AUTOSAR XML (schema 00048)
package /HuaweiMDC/exe_manifests/swcs
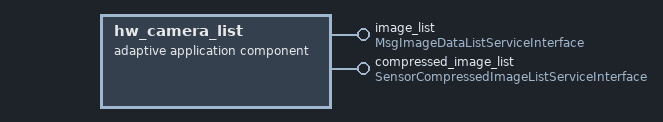
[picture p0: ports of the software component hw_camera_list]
  adaptive application sw component type hw_camera_list
    provide port image_list: provided-interface=MsgImageDataListServiceInterface
    provide port compressed_image_list: provided-interface=SensorCompressedImageListServiceInterface
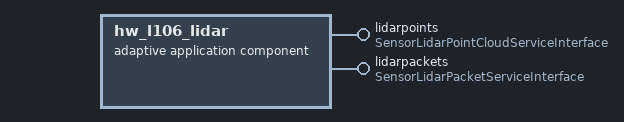
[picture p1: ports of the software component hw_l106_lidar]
  adaptive application sw component type hw_l106_lidar
    provide port lidarpoints: provided-interface=SensorLidarPointCloudServiceInterface
    provide port lidarpackets: provided-interface=SensorLidarPacketServiceInterface
  adaptive application sw component type mid_track_chassis_recv
    provide port tpvehiclestate: provided-interface=VehicleInfomationServiceInterface
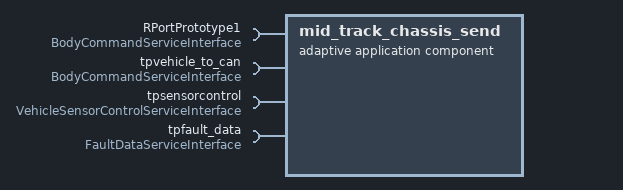
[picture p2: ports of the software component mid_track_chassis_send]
  adaptive application sw component type mid_track_chassis_send
    4 x require port:
      RPortPrototype1: required-interface=BodyCommandServiceInterface
      tpvehicle_to_can: required-interface=BodyCommandServiceInterface
      tpsensorcontrol: required-interface=VehicleSensorControlServiceInterface
      tpfault_data: required-interface=FaultDataServiceInterface
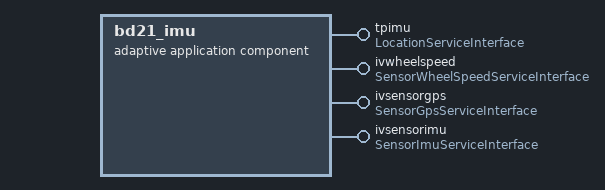
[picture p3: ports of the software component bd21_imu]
  adaptive application sw component type bd21_imu
    4 x provide port:
      tpimu: provided-interface=LocationServiceInterface
      ivwheelspeed: provided-interface=SensorWheelSpeedServiceInterface
      ivsensorgps: provided-interface=SensorGpsServiceInterface
      ivsensorimu: provided-interface=SensorImuServiceInterface
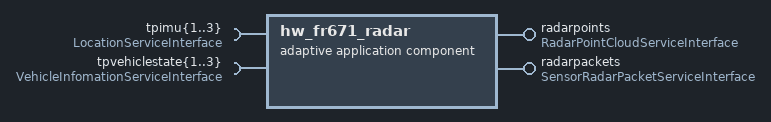
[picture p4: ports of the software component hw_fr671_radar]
  adaptive application sw component type hw_fr671_radar
    provide port radarpoints: provided-interface=RadarPointCloudServiceInterface
    provide port radarpackets: provided-interface=SensorRadarPacketServiceInterface
    6 x require port:
      tpimu{1..3}: required-interface=LocationServiceInterface
      tpvehiclestate{1..3}: required-interface=VehicleInfomationServiceInterface
  adaptive application sw component type lidar_lem_map_det_base
    provide port TerrainMapArrayPPortPrototype
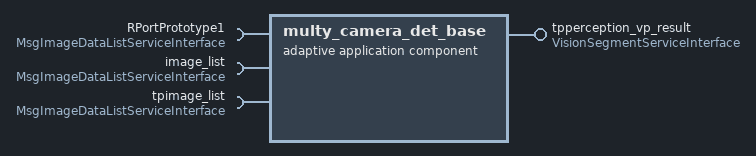
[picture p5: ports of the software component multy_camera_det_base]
  adaptive application sw component type multy_camera_det_base
    provide port tpperception_vp_result: provided-interface=VisionSegmentServiceInterface
    require port RPortPrototype1: required-interface=MsgImageDataListServiceInterface
    require port image_list: required-interface=MsgImageDataListServiceInterface
    require port tpimage_list: required-interface=MsgImageDataListServiceInterface
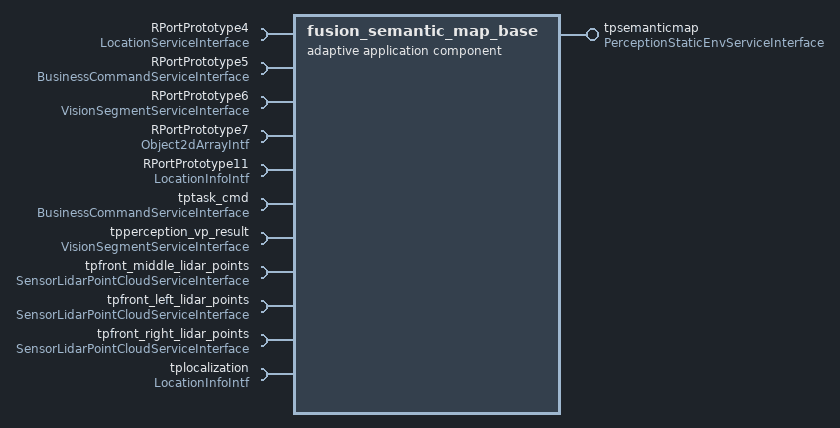
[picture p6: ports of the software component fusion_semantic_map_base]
  adaptive application sw component type fusion_semantic_map_base
    provide port tpsemanticmap: provided-interface=PerceptionStaticEnvServiceInterface
    11 x require port:
      RPortPrototype4: required-interface=LocationServiceInterface
      RPortPrototype5: required-interface=BusinessCommandServiceInterface
      RPortPrototype6: required-interface=VisionSegmentServiceInterface
      RPortPrototype7: required-interface=Object2dArrayIntf
      RPortPrototype11: required-interface=LocationInfoIntf
      tptask_cmd: required-interface=BusinessCommandServiceInterface
      tpperception_vp_result: required-interface=VisionSegmentServiceInterface
      tpfront_middle_lidar_points: required-interface=SensorLidarPointCloudServiceInterface
      tpfront_left_lidar_points: required-interface=SensorLidarPointCloudServiceInterface
      tpfront_right_lidar_points: required-interface=SensorLidarPointCloudServiceInterface
      tplocalization: required-interface=LocationInfoIntf
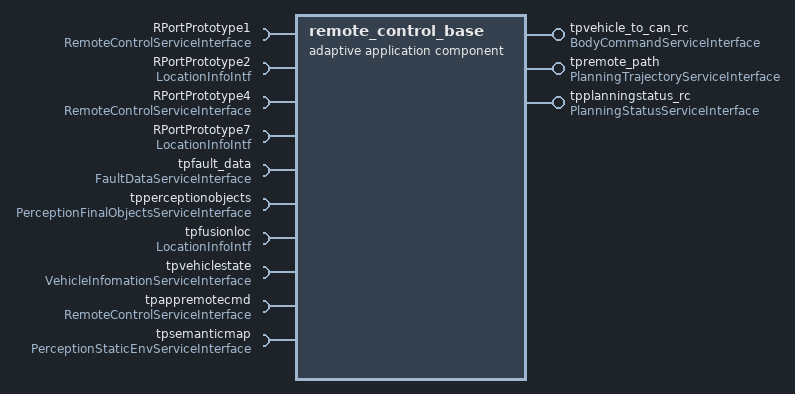
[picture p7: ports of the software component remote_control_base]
  adaptive application sw component type remote_control_base
    provide port tpvehicle_to_can_rc: provided-interface=BodyCommandServiceInterface
    5 x require port:
      RPortPrototype1: required-interface=RemoteControlServiceInterface
      RPortPrototype2: required-interface=LocationInfoIntf
      RPortPrototype4: required-interface=RemoteControlServiceInterface
      RPortPrototype7: required-interface=LocationInfoIntf
      tpfault_data: required-interface=FaultDataServiceInterface
    provide port tpremote_path: provided-interface=PlanningTrajectoryServiceInterface
    provide port tpplanningstatus_rc: provided-interface=PlanningStatusServiceInterface
    5 x require port:
      tpperceptionobjects: required-interface=PerceptionFinalObjectsServiceInterface
      tpfusionloc: required-interface=LocationInfoIntf
      tpvehiclestate: required-interface=VehicleInfomationServiceInterface
      tpappremotecmd: required-interface=RemoteControlServiceInterface
      tpsemanticmap: required-interface=PerceptionStaticEnvServiceInterface
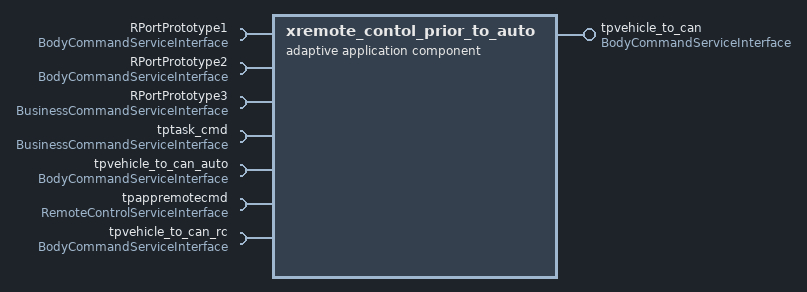
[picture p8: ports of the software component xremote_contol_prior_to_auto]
  adaptive application sw component type xremote_contol_prior_to_auto
    provide port tpvehicle_to_can: provided-interface=BodyCommandServiceInterface
    7 x require port:
      RPortPrototype1: required-interface=BodyCommandServiceInterface
      RPortPrototype2: required-interface=BodyCommandServiceInterface
      RPortPrototype3: required-interface=BusinessCommandServiceInterface
      tptask_cmd: required-interface=BusinessCommandServiceInterface
      tpvehicle_to_can_auto: required-interface=BodyCommandServiceInterface
      tpappremotecmd: required-interface=RemoteControlServiceInterface
      tpvehicle_to_can_rc: required-interface=BodyCommandServiceInterface
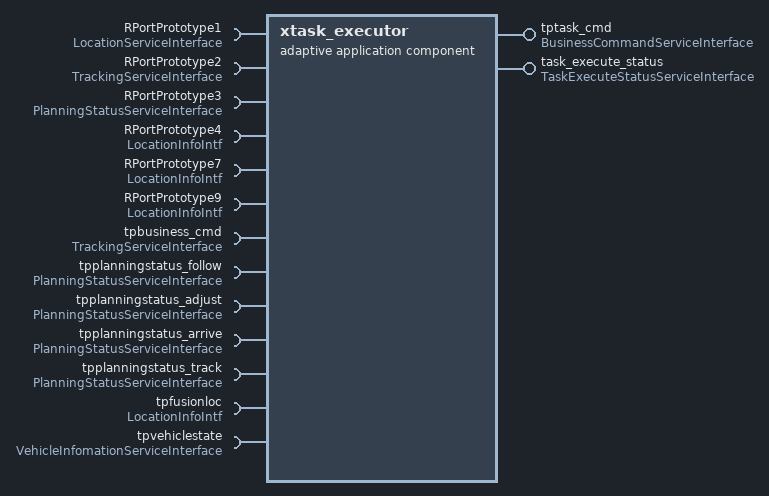
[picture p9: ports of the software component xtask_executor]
  adaptive application sw component type xtask_executor
    provide port tptask_cmd: provided-interface=BusinessCommandServiceInterface
    provide port task_execute_status: provided-interface=TaskExecuteStatusServiceInterface
    13 x require port:
      RPortPrototype1: required-interface=LocationServiceInterface
      RPortPrototype2: required-interface=TrackingServiceInterface
      RPortPrototype3: required-interface=PlanningStatusServiceInterface
      RPortPrototype4: required-interface=LocationInfoIntf
      RPortPrototype7: required-interface=LocationInfoIntf
      RPortPrototype9: required-interface=LocationInfoIntf
      tpbusiness_cmd: required-interface=TrackingServiceInterface
      tpplanningstatus_follow: required-interface=PlanningStatusServiceInterface
      tpplanningstatus_adjust: required-interface=PlanningStatusServiceInterface
      tpplanningstatus_arrive: required-interface=PlanningStatusServiceInterface
      tpplanningstatus_track: required-interface=PlanningStatusServiceInterface
      tpfusionloc: required-interface=LocationInfoIntf
      tpvehiclestate: required-interface=VehicleInfomationServiceInterface
  adaptive application sw component type xvideo_encoder
    provide port SensorImagePPortPrototype: provided-interface=SensorImageServiceInterface
    require port RPortPrototype1: required-interface=MsgImageDataListServiceInterface
    require port RPortPrototype2
  adaptive application sw component type xh265_rtp_pusher
    6 x require port:
      RPortPrototype1
      RPortPrototype2: required-interface=VideoRtpServiceInterface
      RPortPrototype3
      video_rtp_parameter_gcs: required-interface=VideoRtpServiceInterface
      RPortPrototype5
      video_encoded_frame: required-interface=SensorImageServiceInterface
  adaptive application sw component type xzmq_task
    provide port video_rtp_parameter_gcs: provided-interface=VideoRtpServiceInterface
    provide port video_profile: provided-interface=AppVideoProfileServiceInterface
    provide port tpbusiness_cmd: provided-interface=TrackingServiceInterface
    require port RPortPrototype1: required-interface=LocationInfoIntf
    provide port tpsensorcontrol: provided-interface=VehicleSensorControlServiceInterface
    provide port task_manage_status: provided-interface=TaskManageStatusServiceInterface
    7 x require port:
      RPortPrototype4: required-interface=LocationInfoIntf
      task_execute_status: required-interface=TaskExecuteStatusServiceInterface
      RPortPrototype3: required-interface=LocationInfoIntf
      tpvehiclestate: required-interface=VehicleInfomationServiceInterface
      tpperceptionobjects: required-interface=PerceptionFinalObjectsServiceInterface
      tptarget_obj: required-interface=FusionObjectArrayIntf
      tplocalization: required-interface=LocationInfoIntf
  adaptive application sw component type xzmq_rc
    provide port tpappremotecmd: provided-interface=RemoteControlServiceInterface
  adaptive application sw component type ApplicationSwc
  adaptive application sw component type xvideo_editor
    provide port SensorImagePPortPrototype: provided-interface=SensorImageServiceInterface
    require port RPortPrototype1: required-interface=MsgImageDataListServiceInterface
    require port RPortPrototype2
  adaptive application sw component type idptestswc1
    provide port PPortPrototype
  adaptive application sw component type xh265_encoder
    provide port video_encoded_frame: provided-interface=SensorImageServiceInterface
    4 x require port:
      RPortPrototype1: required-interface=SensorImageServiceInterface
      RPortPrototype2: required-interface=SensorImageServiceInterface
      tpimage_for_push: required-interface=SensorImageServiceInterface
      video_profile: required-interface=AppVideoProfileServiceInterface
    provide port video_encoding_perf: provided-interface=VideoEncodingPerfServiceInterface
  adaptive application sw component type hwfr671radarswc
    provide port SensorRadarPPortPrototype: provided-interface=Sensor4DRadarServiceInterface
  adaptive application sw component type locfusionswc
    provide port LocFusionPPortPrototype: provided-interface=LocationInfoIntf
    5 x require port:
      RPortPrototype2: required-interface=RadarPointCloudServiceInterface
      RPortPrototype3: required-interface=LocationServiceInterface
      RPortPrototype4: required-interface=SensorWheelSpeedServiceInterface
      RPortPrototype5: required-interface=SensorGpsServiceInterface
      RPortPrototype1: required-interface=SensorLidarPointCloudServiceInterface
  adaptive application sw component type rtspserverswc
    require port RPortPrototype1
    require port video_encoded_frame: required-interface=SensorImageServiceInterface
  adaptive application sw component type loc_message_fusion
    provide port tplocalization: provided-interface=LocationInfoIntf
    4 x require port:
      RPortPrototype{1..3}: required-interface=LocationInfoIntf
      RPortPrototype4: required-interface=LocationServiceInterface
  adaptive application sw component type lidar_terrain_map_detection
    provide port tpterrainmap: provided-interface=PerceptionStaticEnvServiceInterface
    6 x require port:
      tpfront_right_lidar_points: required-interface=SensorLidarPointCloudServiceInterface
      tpperception_vp_result: required-interface=VisionSegmentServiceInterface
      tplocalization: required-interface=LocationInfoIntf
      tptask_cmd: required-interface=BusinessCommandServiceInterface
      tpfront_middle_lidar_points: required-interface=SensorLidarPointCloudServiceInterface
      tpfront_left_lidar_points: required-interface=SensorLidarPointCloudServiceInterface
  adaptive application sw component type fusion_follow_base
    provide port tpperceptionobjects: provided-interface=PerceptionFinalObjectsServiceInterface
    provide port tptarget_obj: provided-interface=FusionObjectArrayIntf
    12 x require port:
      tptask_cmd: required-interface=BusinessCommandServiceInterface
      tpperception_vp_result: required-interface=VisionSegmentServiceInterface
      RPortPrototype3: required-interface=Object3dArrayIntf
      tpfront_middle_lidar_points: required-interface=SensorLidarPointCloudServiceInterface
      tpfront_left_lidar_points: required-interface=SensorLidarPointCloudServiceInterface
      tpfront_right_lidar_points: required-interface=SensorLidarPointCloudServiceInterface
      tpfront_middle_radar_points: required-interface=RadarPointCloudServiceInterface
      tpfront_left_radar_points: required-interface=RadarPointCloudServiceInterface
      tpfront_right_radar_points: required-interface=RadarPointCloudServiceInterface
      tplocalization: required-interface=LocationInfoIntf
      tplidarobjects: required-interface=Object3dArrayIntf
      tpperception_vp_result: required-interface=VisionSegmentServiceInterface
  adaptive application sw component type planning_adjust_base
    provide port tpplanningstatus_adjust: provided-interface=PlanningStatusServiceInterface
    provide port tppathplan_adjust: provided-interface=EgoTrajectoryServiceInterface
    7 x require port:
      RPortPrototype2: required-interface=LocationInfoIntf
      tptask_cmd: required-interface=BusinessCommandServiceInterface
      tpperceptionobjects: required-interface=PerceptionFinalObjectsServiceInterface
      tpterrainmap: required-interface=PerceptionStaticEnvServiceInterface
      tpfusionloc: required-interface=LocationInfoIntf
      tpvehiclestate: required-interface=VehicleInfomationServiceInterface
      tpsemanticmap: required-interface=PerceptionStaticEnvServiceInterface
  adaptive application sw component type object_following_base
    provide port tpplanningstatus_follow: provided-interface=PlanningStatusServiceInterface
    provide port tppathplan_follow: provided-interface=PlanningTrajectoryServiceInterface
    8 x require port:
      RPortPrototype2: required-interface=LocationInfoIntf
      tptask_cmd: required-interface=BusinessCommandServiceInterface
      tpperceptionobjects: required-interface=PerceptionFinalObjectsServiceInterface
      tpterrainmap: required-interface=PerceptionStaticEnvServiceInterface
      tplocalization: required-interface=LocationInfoIntf
      tpvehiclestate: required-interface=VehicleInfomationServiceInterface
      tpsemanticmap: required-interface=PerceptionStaticEnvServiceInterface
      tptarget_obj: required-interface=FusionObjectArrayIntf
  adaptive application sw component type planning_arrive_base
    provide port tpplanningstatus_arrive: provided-interface=PlanningStatusServiceInterface
    provide port tppathplan_arrive: provided-interface=PlanningTrajectoryServiceInterface
    7 x require port:
      RPortPrototype2: required-interface=LocationInfoIntf
      tptask_cmd: required-interface=BusinessCommandServiceInterface
      tpperceptionobjects: required-interface=PerceptionFinalObjectsServiceInterface
      tpterrainmap: required-interface=PerceptionStaticEnvServiceInterface
      tpfusionloc: required-interface=LocationInfoIntf
      tpvehiclestate: required-interface=VehicleInfomationServiceInterface
      tpsemanticmap: required-interface=PerceptionStaticEnvServiceInterface
  adaptive application sw component type aeb_control_base
    provide port tpvehicle_to_can_auto: provided-interface=BodyCommandServiceInterface
    10 x require port:
      tpvehicle_to_can_pre_aeb: required-interface=BodyCommandServiceInterface
      tpfault_data: required-interface=FaultDataServiceInterface
      tpvehiclestate: required-interface=VehicleInfomationServiceInterface
      RPortPrototype4: required-interface=LocationInfoIntf
      tptask_cmd: required-interface=BusinessCommandServiceInterface
      tpwheelspeed: required-interface=SensorWheelSpeedServiceInterface
      tpfusionloc: required-interface=LocationInfoIntf
      tppathplan_auto: required-interface=PlanningTrajectoryServiceInterface
      tpperceptionobjects: required-interface=PerceptionFinalObjectsServiceInterface
      tpsemanticmap: required-interface=PerceptionStaticEnvServiceInterface
  adaptive application sw component type path_selector_base
    provide port tppathplan_auto: provided-interface=PlanningTrajectoryServiceInterface
    5 x require port:
      tppathplan_adjust: required-interface=EgoTrajectoryServiceInterface
      tppathplan_arrive: required-interface=PlanningTrajectoryServiceInterface
      tppathplan_track: required-interface=PlanningResultIntf
      tppathplan_follow: required-interface=PlanningTrajectoryServiceInterface
      tptask_cmd: required-interface=BusinessCommandServiceInterface
  adaptive application sw component type xzmq_notification
    14 x require port:
      RPortPrototype2: required-interface=LocationInfoIntf
      video_profile: required-interface=AppVideoProfileServiceInterface
      tptask_cmd: required-interface=BusinessCommandServiceInterface
      task_manage_status: required-interface=TaskManageStatusServiceInterface
      tpperceptionobjects: required-interface=PerceptionFinalObjectsServiceInterface
      tptarget_obj: required-interface=FusionObjectArrayIntf
      ivsensorgps: required-interface=SensorGpsServiceInterface
      tpfusionloc: required-interface=LocationInfoIntf
      tpvehicle_to_can: required-interface=BodyCommandServiceInterface
      tpvehiclestate: required-interface=VehicleInfomationServiceInterface
      tpfault_data: required-interface=FaultDataServiceInterface
      tpsemanticmap: required-interface=PerceptionStaticEnvServiceInterface
      video_encoding_perf: required-interface=VideoEncodingPerfServiceInterface
      tpappremotecmd: required-interface=RemoteControlServiceInterface
  adaptive application sw component type mdc_camera_stitch_base
    provide port tpimage_stitich: provided-interface=SensorImageServiceInterface
    require port image_list: required-interface=MsgImageDataListServiceInterface
  adaptive application sw component type xvideo_selector
    require port RPortPrototype4: required-interface=LocationInfoIntf
    provide port tpimage_for_push: provided-interface=SensorImageServiceInterface
    16 x require port:
      tpvideo_profile: required-interface=AppVideoProfileServiceInterface
      tpappremotecmd: required-interface=RemoteControlServiceInterface
      tptask_cmd: required-interface=BusinessCommandServiceInterface
      PerceptionVPResult: required-interface=VisionSegmentServiceInterface
      tppathplan_auto: required-interface=PlanningTrajectoryServiceInterface
      tpremote_path: required-interface=PlanningTrajectoryServiceInterface
      tpimage_stitich: required-interface=SensorImageServiceInterface
      image_list: required-interface=MsgImageDataListServiceInterface
      tpfusionloc: required-interface=LocationInfoIntf
      tpvehiclestate: required-interface=VehicleInfomationServiceInterface
      tpplanningstatus_rc: required-interface=PlanningStatusServiceInterface
      tpplanningstatus_follow: required-interface=PlanningStatusServiceInterface
      tpplanningstatus_adjust: required-interface=PlanningStatusServiceInterface
      tpplanningstatus_arrive: required-interface=PlanningStatusServiceInterface
      tpplanningstatus_track: required-interface=PlanningStatusServiceInterface
      tpsemanticmap: required-interface=PerceptionStaticEnvServiceInterface
  adaptive application sw component type xputimage_shm_server_base
    provide port putimage_out: provided-interface=SensorImageServiceInterface
    require port RPortPrototype1
    require port RPortPrototype2: required-interface=MsgImageDataListServiceInterface
  adaptive application sw component type xdraw_assislines_server_base
    provide port drawassist_image_out: provided-interface=SensorImageServiceInterface
    require port RPortPrototype1
    require port RPortPrototype2: required-interface=SensorImageServiceInterface
  adaptive application sw component type xdraw_obstacles_server_base
    provide port drawassist_image_out: provided-interface=SensorImageServiceInterface
    require port RPortPrototype1: required-interface=SensorImageServiceInterface
    require port RPortPrototype2
  adaptive application sw component type ximage_layout_server_base
    provide port image_for_push: provided-interface=SensorImageServiceInterface
    4 x require port:
      RPortPrototype1: required-interface=SensorImageServiceInterface
      RPortPrototype2
      RPortPrototype3: required-interface=MsgImageDataListServiceInterface
      RPortPrototype4: required-interface=SensorImageServiceInterface
  adaptive application sw component type xh265_recorder
    require port video_encoded_frame: required-interface=SensorImageServiceInterface
  adaptive application sw component type xfault_handler_base
    provide port tpfault_data: provided-interface=FaultDataServiceInterface
    require port tpbusiness_cmd: required-interface=TrackingServiceInterface
    require port tpappremotecmd: required-interface=RemoteControlServiceInterface
  adaptive application sw component type xsystem_monitor
    provide port monitor_data: provided-interface=FaultDataServiceInterface
  adaptive application sw component type xsensor_recorder_base
    provide port recorder_data: provided-interface=FaultDataServiceInterface
    11 x require port:
      RPortPrototype1: required-interface=SensorCompressedImageListServiceInterface
      RPortPrototype{2..4}: required-interface=SensorLidarPacketServiceInterface
      RPortPrototype{5..7}: required-interface=SensorRadarPacketServiceInterface
      RPortPrototype8: required-interface=SensorGpsServiceInterface
      RPortPrototype9: required-interface=LocationServiceInterface
      RPortPrototype10: required-interface=SensorWheelSpeedServiceInterface
      RPortPrototype11: required-interface=VehicleInfomationServiceInterface
  adaptive application sw component type ApplicationSwc
  adaptive application sw component type xdata_trigger_recorder_base
    provide port bag_ondemand_status: provided-interface=BagStatusServiceInterface
    require port tpbusiness_cmd: required-interface=TrackingServiceInterface
    require port tpfault_data: required-interface=FaultDataServiceInterface
  adaptive application sw component type xvehicle_status_recorder_base
    provide port status_recorder: provided-interface=FaultDataServiceInterface
    11 x require port:
      RPortPrototype7: required-interface=LocationInfoIntf
      tpappremotecmd: required-interface=RemoteControlServiceInterface
      tpbusiness_cmd: required-interface=TrackingServiceInterface
      tppathplan_follow: required-interface=PlanningTrajectoryServiceInterface
      tpplanningstatus_follow: required-interface=PlanningStatusServiceInterface
      tpvehicle_to_can_pre_aeb: required-interface=BodyCommandServiceInterface
      tpfusionloc: required-interface=LocationInfoIntf
      ivsensorgps: required-interface=SensorGpsServiceInterface
      tpvehiclestate: required-interface=VehicleInfomationServiceInterface
      tpfault_data: required-interface=FaultDataServiceInterface
      image_list: required-interface=MsgImageDataListServiceInterface
  adaptive application sw component type dev_null_base
    8 x require port:
      RPortPrototype1: required-interface=BagStatusServiceInterface
      RPortPrototype2: required-interface=FaultDataServiceInterface
      RPortPrototype3: required-interface=FaultDataServiceInterface
      monitor_data: required-interface=FaultDataServiceInterface
      RPortPrototype5: required-interface=FaultDataServiceInterface
      RPortPrototype6: required-interface=FaultDataServiceInterface
      status_recorder: required-interface=FaultDataServiceInterface
      bag_ondemand_status: required-interface=BagStatusServiceInterface
  adaptive application sw component type driver_dev_null
    14 x require port:
      compressed_image_list: required-interface=SensorCompressedImageListServiceInterface
      lidarpacketsfront: required-interface=SensorLidarPacketServiceInterface
      lidarpacketsleft: required-interface=SensorLidarPacketServiceInterface
      lidarpacketsright: required-interface=SensorLidarPacketServiceInterface
      radarpacketsright: required-interface=SensorRadarPacketServiceInterface
      radarpacketsfront: required-interface=SensorRadarPacketServiceInterface
      radarpacketsleft: required-interface=SensorRadarPacketServiceInterface
      RPortPrototype1: required-interface=SensorCompressedImageListServiceInterface
      RPortPrototype{2..4}: required-interface=SensorRadarPacketServiceInterface
      RPortPrototype{5..7}: required-interface=SensorLidarPacketServiceInterface
  adaptive application sw component type ApplicationSwc
  adaptive application sw component type ApplicationSwc
    provide port PPortPrototype
  adaptive application sw component type sensor_viualize_base
    4 x require port:
      tplidarfront: required-interface=SensorLidarPointCloudServiceInterface
      tpcameralist: required-interface=MsgImageDataListServiceInterface
      RPortPrototype1: required-interface=RadarPointCloudServiceInterface
      tpfusionloc: required-interface=LocationInfoIntf
  adaptive application sw component type planning_base
    require port RPortPrototype1: required-interface=PerceptionStaticEnvServiceInterface
    require port RPortPrototype2: required-interface=FusionObjectArrayIntf
package /HuaweiMDC/interface_manifests/interfaces
  30 x service interface:
    MsgImageDataListServiceInterface
      namespaces:
        symbol props ara
        symbol props adsfi
      events:
        data EventImageList: type=MsgImageDataList
    SensorCompressedImageListServiceInterface
      namespaces:
        symbol props ara
        symbol props adsfi
      events:
        data EventCompressedImageList: type=MsgImageDataList
    SensorLidarPointCloudServiceInterface
      namespaces:
        symbol props ara
        symbol props adsfi
      events:
        data EventPointCloud2: type=MsgLidarFrame
    SensorLidarPacketServiceInterface
      namespaces:
        symbol props ara
        symbol props adsfi
      events:
        data EventLidarPacket: type=SensorLidarPacket
    VehicleInfomationServiceInterface
      namespaces:
        symbol props ara
        symbol props adsfi
      events:
        data EventVehicleInfo: type=VehicleInformation
    SensorGpsServiceInterface
      namespaces:
        symbol props ara
        symbol props adsfi
      events:
        data EventGps: type=MsgHafGnssInfo
    SensorWheelSpeedServiceInterface
      namespaces:
        symbol props ara
        symbol props adsfi
      events:
        data EventWheelSpeed: type=MsgHafWheelSpeedList
    VisionSegmentServiceInterface
      namespaces:
        symbol props ara
        symbol props adsfi
      events:
        data EventVisionSegment: type=MsgCameraVPResult
    FusionObjectServiceInterface
      namespaces:
        symbol props ara
        symbol props adsfi
      events:
        data EventFusionObject: type=FusionObject
    BusinessCommandServiceInterface
      namespaces:
        symbol props ara
        symbol props adsfi
      events:
        data EventBusinessCommand: type=BusinessCommand
    TaskExecuteStatusServiceInterface
      namespaces:
        symbol props ara
        symbol props adsfi
      events:
        data EventTaskExecuteStatus: type=TaskExecuteStatus
    SensorImageServiceInterface
      namespaces:
        symbol props ara
        symbol props adsfi
      events:
        data EventSensorImage: type=MsgImageData
    VideoRtpServiceInterface
      namespaces:
        symbol props ara
        symbol props adsfi
      events:
        data EventVideoRtpParamter: type=VideoRTPParameter
    TrackingServiceInterface
      namespaces:
        symbol props ara
        symbol props adsif
      events:
        data EventBusinessCommand: type=BusinessCommand
    RadarPointCloudServiceInterface
      namespaces:
        symbol props ara
        symbol props adsfi
      events:
        data EventRadarPointCloud: type=SensorRadarPointCloud
    SensorRadarPacketServiceInterface
      namespaces:
        symbol props ara
        symbol props adsfi
      events:
        data EventSensorRadarPacket: type=SensorRadarPacket
    BodyCommandServiceInterface
      namespaces:
        symbol props ara
        symbol props adsfi
      events:
        data EventVehicleActControl: type=VehicleActControl
    RemoteControlServiceInterface
      namespaces:
        symbol props ara
        symbol props adsfi
      events:
        data EventRCAppRemoteCtl: type=AppRemoteControl
    PlanningStatusServiceInterface
      namespaces:
        symbol props ara
        symbol props adsfi
      events:
        data EventPlanningStatus: type=PlanningStatus
    Sensor4DRadarServiceInterface
      namespaces:
        symbol props ara
        symbol props adsfi
    SensorImuServiceInterface
      namespaces:
        symbol props ara
        symbol props adsfi
      events:
        data EventSensorImu: type=MsgHafIMU
    PerceptionStaticEnvServiceInterface
      namespaces:
        symbol props ara
        symbol props adsfi
      events:
        data EventPerceptionStaticEnv: type=PerceptionStaticEnv
    PerceptionFinalObjectsServiceInterface
      namespaces:
        symbol props ara
        symbol props adsfi
      events:
        data EventPerceptionFinalObjects: type=MsgHafFusionOutArray
    PlanningTrajectoryServiceInterface
      namespaces:
        symbol props ara
        symbol props adsfi
      events:
        data EventPlanningTrajectory: type=MsgHafEgoTrajectory
    TaskManageStatusServiceInterface
      namespaces:
        symbol props ara
        symbol props adsfi
      events:
        data EventTaskManageStatus: type=TaskManageStatus
    AppVideoProfileServiceInterface
      namespaces:
        symbol props ara
        symbol props adsfi
      events:
        data EventAppVideoProfile: type=AppVideoProfile
    VehicleSensorControlServiceInterface
      namespaces:
        symbol props ara
        symbol props adsfi
      events:
        data EventVehicleSensorControl: type=VehicleSensorControl
    FaultDataServiceInterface
      namespaces:
        symbol props ara
        symbol props adsfi
      events:
        data EventFaultData: type=FaultData
    BagStatusServiceInterface
      namespaces:
        symbol props ara
        symbol props adsfi
      events:
        data EventBagStatus: type=FaultData
    VideoEncodingPerfServiceInterface
      namespaces:
        symbol props ara
        symbol props adsfi
      events:
        data EventVideoEncodingPerf: type=VideoEncodingPerf
package /HuaweiMDC/interface_manifests/datatypes
  155 x std cpp implementation data type:
    IdpStringVec: category=VECTOR, cpp-template-argument=String
      namespaces:
        symbol props ara
        symbol props adsfi
    IdpInt64Vec: category=VECTOR, cpp-template-argument=int64_t
      namespaces:
        symbol props ara
        symbol props adsfi
    IdpInt32Vec: category=VECTOR, cpp-template-argument=int32_t
      namespaces:
        symbol props ara
        symbol props adsfi
    IdpInt16Vec: category=VECTOR, cpp-template-argument=int16_t
      namespaces:
        symbol props ara
        symbol props adsfi
    IdpInt8Vec: category=VECTOR, cpp-template-argument=int8_t
      namespaces:
        symbol props ara
        symbol props adsfi
    IdpDoubleVec: category=VECTOR, cpp-template-argument=double
      namespaces:
        symbol props ara
        symbol props adsfi
    IdpFloatVec: category=VECTOR, cpp-template-argument=float
      namespaces:
        symbol props ara
        symbol props adsfi
    IdpUint64Vec: category=VECTOR, cpp-template-argument=uint64_t
      namespaces:
        symbol props ara
        symbol props adsfi
    IdpUint32Vec: category=VECTOR, cpp-template-argument=uint32_t
      namespaces:
        symbol props ara
        symbol props adsfi
    IdpUint16Vec: category=VECTOR, cpp-template-argument=uint16_t
      namespaces:
        symbol props ara
        symbol props adsfi
    IdpUint8Vec: category=VECTOR, cpp-template-argument=uint8_t
      namespaces:
        symbol props ara
        symbol props adsfi
    IdpBoolVec: category=VECTOR, cpp-template-argument=bool
      namespaces:
        symbol props ara
        symbol props adsfi
    MsgHafFloat32WithValid: category=STRUCTURE
      namespaces:
        symbol props ara
        symbol props adsfi
      cpp implementation data type element value: type-reference=float
      cpp implementation data type element confidence: type-reference=uint8_t
    MsgHafTime: category=STRUCTURE
      namespaces:
        symbol props ara
        symbol props adsfi
      cpp implementation data type element sec: type-reference=uint32_t
      cpp implementation data type element nsec: type-reference=uint32_t
    CommonFaultInfo: category=STRUCTURE
      namespaces:
        symbol props ara
        symbol props adsfi
      cpp implementation data type element t: type-reference=double
      cpp implementation data type element info: type-reference=String
      cpp implementation data type element error_code: type-reference=int32_t
    CommonFaultInfoVec: category=VECTOR, cpp-template-argument=CommonFaultInfo
      namespaces:
        symbol props ara
        symbol props adsfi
    CommonTimeChain: category=STRUCTURE
      namespaces:
        symbol props ara
        symbol props adsfi
      4 x cpp implementation data type element, all with category=TYPE_REFERENCE:
        t1: type-reference=double
        t2: type-reference=double
        from_module: type-reference=String
        to_module: type-reference=String
    CommonTimeChainVec: category=VECTOR, cpp-template-argument=CommonTimeChain
      namespaces:
        symbol props ara
        symbol props adsfi
    CommonHeader: category=STRUCTURE
      namespaces:
        symbol props ara
        symbol props adsfi
      7 x cpp implementation data type element, all with category=TYPE_REFERENCE:
        seq: type-reference=int64_t
        time: type-reference=MsgHafTime
        module_name: type-reference=String
        data_name: type-reference=String
        frame_id: type-reference=String
        fault_vec: type-reference=CommonFaultInfoVec
        time_chain_vec: type-reference=datatypes/CommonTimeChainVec
    CommonSensorCalibration: category=STRUCTURE
      namespaces:
        symbol props ara
        symbol props adsfi
      14 x cpp implementation data type element, all with category=TYPE_REFERENCE:
        name: type-reference=String
        prerotaxis_{0..2}: type-reference=int32_t
        prerotdegree_{0..2}: type-reference=float
        xoffset: type-reference=float
        yoffset: type-reference=float
        zoffset: type-reference=float
        roll: type-reference=float
        pitch: type-reference=float
        yaw: type-reference=float
        z_ground_offset: type-reference=float
    CommonUdpPacket: category=STRUCTURE
      namespaces:
        symbol props ara
        symbol props adsfi
      cpp implementation data type element header: type-reference=CommonHeader
      cpp implementation data type element udp_packet: type-reference=IdpUint8Vec
    CommonUdpPacketVec: category=VECTOR, cpp-template-argument=CommonUdpPacket
      namespaces:
        symbol props ara
        symbol props adsfi
    SensorLidarPacket: category=STRUCTURE
      namespaces:
        symbol props ara
        symbol props adsfi
      4 x cpp implementation data type element, all with category=TYPE_REFERENCE:
        header: type-reference=CommonHeader
        calibration: type-reference=CommonSensorCalibration
        msop_packet: type-reference=datatypes/CommonUdpPacketVec
        difop_packet: type-reference=CommonUdpPacket
    MsgPoint3D: category=STRUCTURE
      namespaces:
        symbol props ara
        symbol props adsfi
      cpp implementation data type element x: type-reference=double
      cpp implementation data type element y: type-reference=double
      cpp implementation data type element z: type-reference=double
    MsgPoint3DVec: category=VECTOR, cpp-template-argument=MsgPoint3D
      namespaces:
        symbol props ara
        symbol props adsfi
    MsgHafRect3D: category=STRUCTURE
      namespaces:
        symbol props ara
        symbol props adsfi
      7 x cpp implementation data type element, all with category=TYPE_REFERENCE:
        center: type-reference=MsgPoint3D
        centerCovariance: type-reference=MsgPoint3D
        size: type-reference=MsgPoint3D
        sizeCovariance: type-reference=MsgPoint3D
        orientation: type-reference=float
        orientationCovariance: type-reference=float
        corners: type-reference=datatypes/MsgPoint3DVec
    MsgPoint3f: category=STRUCTURE
      namespaces:
        symbol props ara
        symbol props adsfi
      cpp implementation data type element x: type-reference=float
      cpp implementation data type element y: type-reference=float
      cpp implementation data type element z: type-reference=float
    MsgPoint3fVec: category=VECTOR, cpp-template-argument=MsgPoint3f
      namespaces:
        symbol props ara
        symbol props adsfi
    MsgHaf3dDetectionOut: category=STRUCTURE
      namespaces:
        symbol props ara
        symbol props adsfi
      14 x cpp implementation data type element, all with category=TYPE_REFERENCE:
        objectId: type-reference=int32_t
        cls: type-reference=uint32_t
        types: type-reference=uint32_t
        confidence: type-reference=float
        existenceProbability: type-reference=float
        coordinate: type-reference=String
        rect: type-reference=MsgHafRect3D
        velocity: type-reference=MsgPoint3f
        contourPoints: type-reference=datatypes/MsgPoint3fVec
        timeCreation: type-reference=MsgHafTime
        acceleration: type-reference=MsgPoint3D
        blinkerStatus: type-reference=uint32_t
        cipvFlag: type-reference=uint32_t
        cameraStatus: type-reference=uint8_t
    AppStatusMessage: category=STRUCTURE
      namespaces:
        symbol props ara
        symbol props adsfi
      cpp implementation data type element status: type-reference=String
      cpp implementation data type element error_msg: type-reference=String
    VehicleSensorControl: category=STRUCTURE
      namespaces:
        symbol props ara
        symbol props adsfi
      31 x cpp implementation data type element, all with category=TYPE_REFERENCE:
        header: type-reference=CommonHeader
        chassis_enable: type-reference=uint8_t
        operate_mode: type-reference=uint8_t
        motor_mode: type-reference=uint8_t
        motor_power: type-reference=uint8_t
        limit_speed: type-reference=uint8_t
        high_pressure: type-reference=uint8_t
        motor_drive_mode: type-reference=uint8_t
        offroad_mode: type-reference=uint8_t
        parking_mode: type-reference=uint8_t
        pump_control1: type-reference=uint8_t
        pump_control2: type-reference=uint8_t
        flann_control: type-reference=uint8_t
        headlights_low_beam: type-reference=uint8_t
        headlights_hight_beam: type-reference=uint8_t
        turnleft_light: type-reference=uint8_t
        turnright_light: type-reference=uint8_t
        position_light: type-reference=uint8_t
        double_floash: type-reference=uint8_t
        horn: type-reference=uint8_t
        drainage_pump: type-reference=uint8_t
        radar_control: type-reference=uint8_t
        lidar_control: type-reference=uint8_t
        night_vision_control: type-reference=uint8_t
        domain_control: type-reference=uint8_t
        MDC_temp: type-reference=uint8_t
        reserve1: type-reference=uint8_t
        reserve2: type-reference=uint8_t
        battery_heating: type-reference=uint8_t
        power_out_control: type-reference=uint8_t
        battery_warming: type-reference=uint8_t
    VehicleLonControl: category=STRUCTURE
      namespaces:
        symbol props ara
        symbol props adsfi
      8 x cpp implementation data type element, all with category=TYPE_REFERENCE:
        target_speed: type-reference=float
        target_torque: type-reference=float
        target_pressure: type-reference=float
        actuator_mode: type-reference=uint8_t
        emergency_mode: type-reference=uint8_t
        handbrake: type-reference=uint8_t
        shift_position: type-reference=uint8_t
        control_mode: type-reference=uint8_t
    MsgHafRadarModeDatainfo: category=STRUCTURE
      namespaces:
        symbol props ara
        symbol props adsfi
      5 x cpp implementation data type element, all with category=TYPE_REFERENCE:
        x: type-reference=double
        y: type-reference=double
        z: type-reference=double
        rms: type-reference=MsgPoint3D
        quality: type-reference=MsgPoint3D
    MsgHafRadarDetectData: category=STRUCTURE
      namespaces:
        symbol props ara
        symbol props adsfi
      13 x cpp implementation data type element, all with category=TYPE_REFERENCE:
        id: type-reference=uint8_t
        idPair: type-reference=uint8_t
        coordinate: type-reference=uint8_t
        position: type-reference=MsgHafRadarModeDatainfo
        velocity: type-reference=MsgHafRadarModeDatainfo
        acceleration: type-reference=MsgHafRadarModeDatainfo
        rcs: type-reference=double
        snr: type-reference=double
        existProbability: type-reference=uint8_t
        falseProbability: type-reference=uint8_t
        movProperty: type-reference=uint8_t
        invalidState: type-reference=uint8_t
        ambiguity: type-reference=uint8_t
    BusniessRemoteControl: category=STRUCTURE
      namespaces:
        symbol props ara
        symbol props adsfi
      11 x cpp implementation data type element, all with category=TYPE_REFERENCE:
        steering_wheel: type-reference=double
        gear: type-reference=int32_t
        brake: type-reference=double
        accelerator: type-reference=double
        remotectrl_flag: type-reference=int32_t
        estop_flag: type-reference=int32_t
        steer_torque: type-reference=double
        eng_status: type-reference=bool
        ctrl_level: type-reference=int32_t
        tick: type-reference=int32_t
        in_place: type-reference=bool
    VehicleLatControl: category=STRUCTURE
      namespaces:
        symbol props ara
        symbol props adsfi
      5 x cpp implementation data type element, all with category=TYPE_REFERENCE:
        target_angle: type-reference=float
        target_torque: type-reference=float
        centor_control_value: type-reference=int8_t
        target_curvature: type-reference=float
        steer_control_mode: type-reference=int32_t
    CommonTimeChainVec: category=VECTOR, cpp-template-argument=CommonTimeChain
      namespaces:
        symbol props ara
        symbol props adsfi
    MsgPoint2D: category=STRUCTURE
      namespaces:
        symbol props ara
        symbol props adsfi
      cpp implementation data type element x: type-reference=double
      cpp implementation data type element y: type-reference=double
    MsgPoint2DVec: category=VECTOR, cpp-template-argument=MsgPoint2D
      namespaces:
        symbol props ara
        symbol props adsfi
    MsgHafRect2D: category=STRUCTURE
      namespaces:
        symbol props ara
        symbol props adsfi
      8 x cpp implementation data type element, all with category=TYPE_REFERENCE:
        center: type-reference=MsgPoint2D
        location: type-reference=MsgPoint2D
        centerCovariance: type-reference=MsgPoint2D
        size: type-reference=MsgPoint2D
        sizeCovariance: type-reference=MsgPoint2D
        orientation: type-reference=float
        orientationCovariance: type-reference=float
        corners: type-reference=datatypes/MsgPoint2DVec
    MsgPoint3DVec: category=VECTOR, cpp-template-argument=MsgPoint3D
      namespaces:
        symbol props ara
        symbol props adsfi
    MsgHafFusionOut: category=STRUCTURE
      namespaces:
        symbol props ara
        symbol props adsfi
      23 x cpp implementation data type element, all with category=TYPE_REFERENCE:
        objectID: type-reference=int32_t
        cs: type-reference=uint32_t
        confidence: type-reference=float
        existenceProbability: type-reference=float
        rect: type-reference=MsgHafRect3D
        rect_2d: type-reference=MsgHafRect2D
        absRect: type-reference=MsgHafRect3D
        velocity: type-reference=MsgPoint3f
        absVelocity: type-reference=MsgPoint3f
        velocityCovariance: type-reference=IdpDoubleVec
        absVelocityCovariance: type-reference=IdpDoubleVec
        acceleration: type-reference=MsgPoint3D
        absAcceleration: type-reference=MsgPoint3D
        accelerationCovariance: type-reference=IdpDoubleVec
        absAccelerationCovariance: type-reference=IdpDoubleVec
        pathPoints: type-reference=datatypes/MsgPoint3DVec
        timeCreation: type-reference=MsgHafTime
        lastUpdatedTime: type-reference=MsgHafTime
        cipvFlag: type-reference=uint8_t
        blinkerFlag: type-reference=uint8_t
        fusionType: type-reference=uint8_t
        anchorPoint: type-reference=MsgPoint3D
        absAnchorPoint: type-reference=MsgPoint3D
    MsgHafFusionOutVec: category=VECTOR, cpp-template-argument=MsgHafFusionOut
      namespaces:
        symbol props ara
        symbol props adsfi
    MsgHafFusionOutArray: category=STRUCTURE
      namespaces:
        symbol props ara
        symbol props adsfi
      6 x cpp implementation data type element, all with category=TYPE_REFERENCE:
        stamp: type-reference=MsgHafTime
        time_chain_vec: type-reference=datatypes/CommonTimeChainVec
        count: type-reference=int32_t
        fusionOut: type-reference=MsgHafFusionOutVec
        frameID: type-reference=String
        seq: type-reference=uint32_t
    CommonTimeChainVec: category=VECTOR, cpp-template-argument=CommonTimeChain
      namespaces:
        symbol props ara
        symbol props adsfi
    MsgHafHeader: category=STRUCTURE
      namespaces:
        symbol props ara
        symbol props adsfi
      4 x cpp implementation data type element, all with category=TYPE_REFERENCE:
        seq: type-reference=uint32_t
        timestamp: type-reference=MsgHafTime
        frameID: type-reference=String
        time_chain_vec: type-reference=datatypes/CommonTimeChainVec
    MsgHafWayPoint: category=STRUCTURE
      namespaces:
        symbol props ara
        symbol props adsfi
      14 x cpp implementation data type element, all with category=TYPE_REFERENCE:
        header: type-reference=MsgHafHeader
        xg: type-reference=double
        yg: type-reference=double
        zg: type-reference=double
        x: type-reference=double
        y: type-reference=double
        angle: type-reference=double
        theta: type-reference=double
        curvature: type-reference=double
        s: type-reference=double
        deltaCurvature: type-reference=double
        laneId: type-reference=String
        deltaX: type-reference=double
        deltaY: type-reference=double
    MsgHafTrajectoryPoint: category=STRUCTURE
      namespaces:
        symbol props ara
        symbol props adsfi
      9 x cpp implementation data type element, all with category=TYPE_REFERENCE:
        header: type-reference=MsgHafHeader
        wayPoint: type-reference=MsgHafWayPoint
        speed: type-reference=double
        acc: type-reference=double
        timeRelative: type-reference=double
        deltaAcc: type-reference=double
        steerAngle: type-reference=double
        length: type-reference=float
        risk_level: type-reference=int32_t
    MsgHafTrajectoryPointVec: category=VECTOR, cpp-template-argument=MsgHafTrajectoryPoint
      namespaces:
        symbol props ara
        symbol props adsfi
    MsgHafWayPointVec: category=VECTOR, cpp-template-argument=MsgHafWayPoint
      namespaces:
        symbol props ara
        symbol props adsfi
    MsgHafEstop: category=STRUCTURE
      namespaces:
        symbol props ara
        symbol props adsfi
      cpp implementation data type element header: type-reference=MsgHafHeader
      cpp implementation data type element isEstop: type-reference=uint8_t
      cpp implementation data type element description: type-reference=String
    MsgHafEgoTrajectory: category=STRUCTURE
      namespaces:
        symbol props ara
        symbol props adsfi
      14 x cpp implementation data type element, all with category=TYPE_REFERENCE:
        egoTrajectoryHeader: type-reference=MsgHafHeader
        trajectoryLength: type-reference=double
        trajectoryPeriod: type-reference=double
        trajectoryPoints: type-reference=MsgHafTrajectoryPointVec
        wayPoints: type-reference=MsgHafWayPointVec
        isReplanning: type-reference=uint8_t
        gear: type-reference=uint8_t
        estop: type-reference=MsgHafEstop
        routingHeader: type-reference=MsgHafHeader
        selfLaneid: type-reference=String
        trajectoryType: type-reference=int32_t
        targetLaneId: type-reference=String
        turnLight: type-reference=uint8_t
        isHeld: type-reference=uint8_t
    MsgPoint3DVec: category=VECTOR, cpp-template-argument=MsgPoint3D
      namespaces:
        symbol props ara
        symbol props adsfi
    AppVideoSplitPoint: category=STRUCTURE
      namespaces:
        symbol props ara
        symbol props adsfi
      4 x cpp implementation data type element, all with category=TYPE_REFERENCE, type-reference=int32_t:
        left_top_point_x
        left_top_point_y
        right_bottom_point_x
        right_bottom_point_y
    AppVideoSplitParam: category=STRUCTURE
      namespaces:
        symbol props ara
        symbol props adsfi
      cpp implementation data type element channel_name: type-reference=String
      cpp implementation data type element view_area_points: type-reference=AppVideoSplitPoint
      cpp implementation data type element crop_area_points: type-reference=AppVideoSplitPoint
    AppVideoSplitParamVec: category=VECTOR, cpp-template-argument=AppVideoSplitParam
      namespaces:
        symbol props ara
        symbol props adsfi
    AppVideoEditorParameter: category=STRUCTURE
      namespaces:
        symbol props ara
        symbol props adsfi
      15 x cpp implementation data type element, all with category=TYPE_REFERENCE:
        output_mode: type-reference=int32_t
        remote_control_alarm: type-reference=int32_t
        remote_control_assist: type-reference=int32_t
        front_source: type-reference=int32_t
        split_adaptive: type-reference=int32_t
        video_left_: type-reference=int32_t
        video_main_: type-reference=int32_t
        video_right_: type-reference=int32_t
        objects: type-reference=MsgHafFusionOutArray
        remote_control: type-reference=MsgHafEgoTrajectory
        path: type-reference=MsgHafEgoTrajectory
        target_points: type-reference=datatypes/MsgPoint3DVec
        video_third_person: type-reference=int32_t
        target_point: type-reference=MsgPoint3D
        split_parames_: type-reference=datatypes/AppVideoSplitParamVec
    MsgHafPose: category=STRUCTURE
      namespaces:
        symbol props ara
        symbol props adsfi
      cpp implementation data type element position: type-reference=MsgPoint3D
      cpp implementation data type element orientation: type-reference=MsgPoint3D
    MsgHafPoseWithCovariance: category=STRUCTURE
      namespaces:
        symbol props ara
        symbol props adsfi
      cpp implementation data type element pose: type-reference=MsgHafPose
      cpp implementation data type element covariance: type-reference=IdpDoubleVec
    MsgHafTwist: category=STRUCTURE
      namespaces:
        symbol props ara
        symbol props adsfi
      cpp implementation data type element linear: type-reference=MsgPoint3D
      cpp implementation data type element angular: type-reference=MsgPoint3D
    MsgHafTwistWithCovariance: category=STRUCTURE
      namespaces:
        symbol props ara
        symbol props adsfi
      cpp implementation data type element twist: type-reference=MsgHafTwist
      cpp implementation data type element covariance: type-reference=IdpDoubleVec
    MsgHafAccel: category=STRUCTURE
      namespaces:
        symbol props ara
        symbol props adsfi
      cpp implementation data type element linear: type-reference=MsgPoint3D
      cpp implementation data type element angular: type-reference=MsgPoint3D
    MsgHafAccelWithCovariance: category=STRUCTURE
      namespaces:
        symbol props ara
        symbol props adsfi
      cpp implementation data type element accel: type-reference=MsgHafAccel
      cpp implementation data type element covariance: type-reference=IdpDoubleVec
    MsgHafLocation: category=STRUCTURE
      namespaces:
        symbol props ara
        symbol props adsfi
      10 x cpp implementation data type element, all with category=TYPE_REFERENCE:
        header: type-reference=MsgHafHeader
        llh: type-reference=MsgPoint3D
        pose: type-reference=MsgHafPoseWithCovariance
        dr_pose: type-reference=MsgHafPoseWithCovariance
        velocity: type-reference=MsgHafTwistWithCovariance
        acceleration: type-reference=MsgHafAccelWithCovariance
        v: type-reference=double
        locationState: type-reference=uint16_t
        gnssState: type-reference=uint16_t
        odomType: type-reference=uint8_t
    VideoEncodingPerf: category=STRUCTURE
      namespaces:
        symbol props ara
        symbol props adsfi
      8 x cpp implementation data type element, all with category=TYPE_REFERENCE:
        header: type-reference=MsgHafHeader
        avg_ms_scaling: type-reference=double
        avg_ms_color_converting: type-reference=double
        avg_ms_encoding: type-reference=double
        avg_ms_sending: type-reference=double
        avg_ms_span_from_driver_to_scale: type-reference=double
        fps: type-reference=float
        avg_ms_span_from_driver_to_send_done: type-reference=double
    MsgPoint3fVec: category=VECTOR, cpp-template-argument=MsgPoint3f
      namespaces:
        symbol props ara
        symbol props adsfi
    AppVideoSplitParamVec: category=VECTOR, cpp-template-argument=AppVideoSplitParam
      namespaces:
        symbol props ara
        symbol props adsfi
    AppVideoProfile: category=STRUCTURE
      namespaces:
        symbol props ara
        symbol props adsfi
      20 x cpp implementation data type element, all with category=TYPE_REFERENCE:
        header: type-reference=CommonHeader
        front_source: type-reference=int32_t
        output_mode: type-reference=int32_t
        adaptive_mode: type-reference=int32_t
        manual_bps: type-reference=int32_t
        manual_width: type-reference=double
        manual_height: type-reference=double
        remote_control_assist: type-reference=int32_t
        remote_control_alarm: type-reference=int32_t
        split_adaptive: type-reference=int32_t
        manual_split_main: type-reference=int32_t
        manual_split_left: type-reference=int32_t
        manual_split_right: type-reference=int32_t
        receiver_reported_fps: type-reference=double
        receiver_reported_bps: type-reference=double
        receiver_reported_ts: type-reference=int64_t
        points: type-reference=datatypes/MsgPoint3fVec
        video_third_person: type-reference=int32_t
        split_area_parames: type-reference=datatypes/AppVideoSplitParamVec
        auto_control_assist: type-reference=int32_t
    FaultInfo: category=STRUCTURE
      namespaces:
        symbol props ara
        symbol props adsfi
      6 x cpp implementation data type element, all with category=TYPE_REFERENCE:
        code: type-reference=String
        handle: type-reference=int32_t
        desc: type-reference=String
        extra_desc: type-reference=String
        timestamp: type-reference=double
        from: type-reference=String
    FaultInfoVec: category=VECTOR, cpp-template-argument=FaultInfo
      namespaces:
        symbol props ara
        symbol props adsfi
    FaultData: category=STRUCTURE
      namespaces:
        symbol props ara
        symbol props adsfi
      cpp implementation data type element header: type-reference=CommonHeader
      cpp implementation data type element fault_info: type-reference=FaultInfoVec
      cpp implementation data type element fault_level: type-reference=int32_t
    MsgHafRadarTrackOrient: category=STRUCTURE
      namespaces:
        symbol props ara
        symbol props adsfi
      cpp implementation data type element orientation: type-reference=double
      cpp implementation data type element rms: type-reference=double
      cpp implementation data type element quality: type-reference=double
    MsgHafRadarTrackYaw: category=STRUCTURE
      namespaces:
        symbol props ara
        symbol props adsfi
      cpp implementation data type element yawRate: type-reference=double
      cpp implementation data type element rms: type-reference=double
      cpp implementation data type element quality: type-reference=double
    MsgHafRadarTrackData: category=STRUCTURE
      namespaces:
        symbol props ara
        symbol props adsfi
      18 x cpp implementation data type element, all with category=TYPE_REFERENCE:
        id: type-reference=uint8_t
        idState: type-reference=uint8_t
        lifetime: type-reference=uint8_t
        position: type-reference=MsgHafRadarModeDatainfo
        velocity: type-reference=MsgHafRadarModeDatainfo
        acceleration: type-reference=MsgHafRadarModeDatainfo
        size: type-reference=MsgHafRadarModeDatainfo
        orient: type-reference=MsgHafRadarTrackOrient
        yaw: type-reference=MsgHafRadarTrackYaw
        rcs: type-reference=double
        snr: type-reference=double
        underpassProbability: type-reference=double
        overpassProbability: type-reference=double
        existProbability: type-reference=uint8_t
        movProperty: type-reference=uint8_t
        trackState: type-reference=uint8_t
        trackType: type-reference=uint8_t
        heading: type-reference=double
    MsgHafWheelSpeed: category=STRUCTURE
      namespaces:
        symbol props ara
        symbol props adsfi
      6 x cpp implementation data type element, all with category=TYPE_REFERENCE:
        wheelDirection: type-reference=uint8_t
        wheelCount: type-reference=int32_t
        wheelSpeedMps: type-reference=float
        wheelCountValid: type-reference=uint8_t
        wheelSpeedMpsValid: type-reference=uint8_t
        wheelSpeedPos: type-reference=uint8_t
    MsgHafWheelSpeedVec: category=VECTOR, cpp-template-argument=MsgHafWheelSpeed
      namespaces:
        symbol props ara
        symbol props adsfi
    MsgHafWheelSpeedList: category=STRUCTURE
      namespaces:
        symbol props ara
        symbol props adsfi
      cpp implementation data type element header: type-reference=MsgHafHeader
      cpp implementation data type element wheel_speed_vec: type-reference=MsgHafWheelSpeedVec
    MsgHaf3dDetectionOutVec: category=VECTOR, cpp-template-argument=MsgHaf3dDetectionOut
      namespaces:
        symbol props ara
        symbol props adsfi
    MsgHaf2dDetectionOut: category=STRUCTURE
      namespaces:
        symbol props ara
        symbol props adsfi
      12 x cpp implementation data type element, all with category=TYPE_REFERENCE:
        objectId: type-reference=int32_t
        cls: type-reference=uint8_t
        confidence: type-reference=float
        existenceProbability: type-reference=float
        coordinate: type-reference=String
        rect: type-reference=MsgHafRect2D
        velocity: type-reference=MsgPoint2D
        timeCreation: type-reference=MsgHafTime
        acceleration: type-reference=MsgPoint3D
        blinkerStatus: type-reference=uint8_t
        cipvFlag: type-reference=uint8_t
        cameraStatus: type-reference=uint8_t
    MsgHaf2dDetectionOutVec: category=VECTOR, cpp-template-argument=MsgHaf2dDetectionOut
      namespaces:
        symbol props ara
        symbol props adsfi
    CommonTimeChainVec: category=VECTOR, cpp-template-argument=CommonTimeChain
      namespaces:
        symbol props ara
        symbol props adsfi
    MsgHaf3dDetectionOutArray: category=STRUCTURE
      namespaces:
        symbol props ara
        symbol props adsfi
      7 x cpp implementation data type element, all with category=TYPE_REFERENCE:
        timestamp: type-reference=MsgHafTime
        count: type-reference=int32_t
        detectionOut3d: type-reference=MsgHaf3dDetectionOutVec
        detectionOut2d: type-reference=MsgHaf2dDetectionOutVec
        frameID: type-reference=String
        seq: type-reference=uint32_t
        time_chain_vec: type-reference=datatypes/CommonTimeChainVec
    MsgImageData: category=STRUCTURE
      namespaces:
        symbol props ara
        symbol props adsfi
      10 x cpp implementation data type element, all with category=TYPE_REFERENCE:
        timestamp: type-reference=MsgHafTime
        frameID: type-reference=String
        width: type-reference=uint32_t
        height: type-reference=uint32_t
        dataSize: type-reference=uint32_t
        bufferType: type-reference=uint8_t
        imageType: type-reference=uint8_t
        seq: type-reference=uint32_t
        rawData: type-reference=IdpUint8Vec
        mbufData: type-reference=int64_t
    MsgImageDataVec: category=VECTOR, cpp-template-argument=MsgImageData
      namespaces:
        symbol props ara
        symbol props adsfi
    MsgCameraDetectionResult: category=STRUCTURE
      namespaces:
        symbol props ara
        symbol props adsfi
      cpp implementation data type element header: type-reference=MsgHafHeader
      cpp implementation data type element image_objects: type-reference=MsgHaf3dDetectionOutArray
      cpp implementation data type element image_segmentation_vec: type-reference=datatypes/MsgImageDataVec
    AppGlobalPatrolControlParameter: category=STRUCTURE
      namespaces:
        symbol props ara
        symbol props adsfi
      8 x cpp implementation data type element, all with category=TYPE_REFERENCE:
        command: type-reference=String
        file_track: type-reference=String
        file_map: type-reference=String
        file_task: type-reference=String
        dest: type-reference=String
        roads_info: type-reference=String
        type: type-reference=int32_t
        is_loop: type-reference=bool
    MsgPointXYZIRT: category=STRUCTURE
      namespaces:
        symbol props ara
        symbol props adsfi
      7 x cpp implementation data type element, all with category=TYPE_REFERENCE:
        x: type-reference=float
        y: type-reference=float
        z: type-reference=float
        angle: type-reference=float
        intensity: type-reference=uint16_t
        ring: type-reference=uint16_t
        latency: type-reference=uint32_t
    MsgPointXYZIRTVec: category=VECTOR, cpp-template-argument=MsgPointXYZIRT
      namespaces:
        symbol props ara
        symbol props adsfi
    MsgLidarFrame: category=STRUCTURE
      namespaces:
        symbol props ara
        symbol props adsfi
      4 x cpp implementation data type element, all with category=TYPE_REFERENCE:
        timestamp: type-reference=MsgHafTime
        seq: type-reference=uint32_t
        frameID: type-reference=String
        pointCloud: type-reference=MsgPointXYZIRTVec
    PerceptionTerrainPatch: category=STRUCTURE
      namespaces:
        symbol props ara
        symbol props adsfi
      5 x cpp implementation data type element:
        patch_center: type-reference=MsgPoint3f
        slopx: type-reference=float
        slopy: type-reference=float
        type: type-reference=uint8_t
        terrain_height: type-reference=Float
    AppSoftControl: category=STRUCTURE
      namespaces:
        symbol props ara
        symbol props adsfi
      4 x cpp implementation data type element, all with category=TYPE_REFERENCE:
        low_beam_ctrl: type-reference=int32_t
        max_speed: type-reference=float
        other_ctrl: type-reference=int32_t
        record_return_path: type-reference=int32_t
    AppVideoEncodingParameter: category=STRUCTURE
      namespaces:
        symbol props ara
        symbol props adsfi
      8 x cpp implementation data type element, all with category=TYPE_REFERENCE:
        adaptive_mode: type-reference=int32_t
        rate_control_mode: type-reference=int32_t
        quality: type-reference=int32_t
        bps: type-reference=int32_t
        fps: type-reference=int32_t
        encoding_gop: type-reference=int32_t
        width: type-reference=double
        height: type-reference=double
    AppVideoParameter: category=STRUCTURE
      namespaces:
        symbol props ara
        symbol props adsfi
      cpp implementation data type element editor_parameter: type-reference=AppVideoEditorParameter
      cpp implementation data type element encoding_parameter: type-reference=AppVideoEncodingParameter
    VehicleActState: category=STRUCTURE
      namespaces:
        symbol props ara
        symbol props adsfi
      11 x cpp implementation data type element, all with category=TYPE_REFERENCE:
        throttle_info: type-reference=float
        steer_angle: type-reference=float
        steer_curvature: type-reference=float
        speed: type-reference=float
        acceleration: type-reference=float
        shift_position: type-reference=uint8_t
        aeb_active: type-reference=uint8_t
        parking_mode_status: type-reference=uint8_t
        epb_status: type-reference=uint8_t
        drive_mode: type-reference=uint8_t
        steering_mode_status: type-reference=uint8_t
    MsgPoint2DVec: category=VECTOR, cpp-template-argument=MsgPoint2D
      namespaces:
        symbol props ara
        symbol props adsfi
    PerceptionUtraData: category=STRUCTURE
      namespaces:
        symbol props ara
        symbol props adsfi
      5 x cpp implementation data type element, all with category=TYPE_REFERENCE:
        trigger_stamp: type-reference=double
        id: type-reference=int32_t
        dis: type-reference=float
        angle: type-reference=float
        cells: type-reference=datatypes/MsgPoint2DVec
    AppImage: category=STRUCTURE
      namespaces:
        symbol props ara
        symbol props adsfi
      6 x cpp implementation data type element, all with category=TYPE_REFERENCE:
        header: type-reference=CommonHeader
        height: type-reference=int32_t
        width: type-reference=int32_t
        encoding: type-reference=String
        step: type-reference=int32_t
        data: type-reference=IdpUint8Vec
    TaskManageStatus: category=STRUCTURE
      namespaces:
        symbol props ara
        symbol props adsfi
      9 x cpp implementation data type element, all with category=TYPE_REFERENCE:
        header: type-reference=CommonHeader
        action_id: type-reference=uint8_t
        task_status: type-reference=uint8_t
        task_type: type-reference=uint8_t
        task_progress: type-reference=uint8_t
        distance_to_nearest: type-reference=double
        total_mileage: type-reference=double
        current_mileage: type-reference=double
        progress: type-reference=uint8_t
    AppPatrolControlParameter: category=STRUCTURE
      namespaces:
        symbol props ara
        symbol props adsfi
      7 x cpp implementation data type element, all with category=TYPE_REFERENCE:
        command: type-reference=String
        file_track: type-reference=String
        file_map: type-reference=String
        file_task: type-reference=String
        dest: type-reference=String
        type: type-reference=int32_t
        is_loop: type-reference=bool
    MsgTimeStampInfo: category=STRUCTURE
      namespaces:
        symbol props ara
        symbol props adsfi
      cpp implementation data type element timeStampStatus: type-reference=uint16_t
      cpp implementation data type element timeStamp: type-reference=int64_t
      cpp implementation data type element autoSarTimeStamp: type-reference=int64_t
    PerceptionLWH: category=STRUCTURE
      namespaces:
        symbol props ara
        symbol props adsfi
      cpp implementation data type element width: type-reference=float
      cpp implementation data type element length: type-reference=float
      cpp implementation data type element height: type-reference=float
    PerceptionSemanticCell: category=STRUCTURE
      namespaces:
        symbol props ara
        symbol props adsfi
      5 x cpp implementation data type element, all with category=TYPE_REFERENCE:
        x: type-reference=float
        y: type-reference=float
        xg: type-reference=double
        yg: type-reference=double
        dh: type-reference=float
    PerceptionSemanticCellVec: category=VECTOR, cpp-template-argument=PerceptionSemanticCell
      namespaces:
        symbol props ara
        symbol props adsfi
    PerceptionSemanticObj: category=STRUCTURE
      namespaces:
        symbol props ara
        symbol props adsfi
      12 x cpp implementation data type element, all with category=TYPE_REFERENCE:
        x: type-reference=float
        y: type-reference=float
        xg: type-reference=double
        yg: type-reference=double
        z: type-reference=float
        type: type-reference=uint8_t
        obj_size: type-reference=PerceptionLWH
        heading: type-reference=float
        speed: type-reference=float
        cells: type-reference=PerceptionSemanticCellVec
        plan_risk_level: type-reference=int32_t
        rect_2d: type-reference=MsgHafRect2D
    AppPatrolDynamicParameter: category=STRUCTURE
      namespaces:
        symbol props ara
        symbol props adsfi
      cpp implementation data type element avoid: type-reference=int32_t
      cpp implementation data type element speed: type-reference=double
      cpp implementation data type element paused: type-reference=bool
    VideoReceiverReport: category=STRUCTURE
      namespaces:
        symbol props ara
        symbol props adsfi
      4 x cpp implementation data type element, all with category=TYPE_REFERENCE:
        ts: type-reference=int64_t
        fps: type-reference=double
        bps: type-reference=double
        total_latency: type-reference=double
    VideoReceiverReportVec: category=VECTOR, cpp-template-argument=VideoReceiverReport
      namespaces:
        symbol props ara
        symbol props adsfi
    VideoReceiverReports: category=STRUCTURE
      namespaces:
        symbol props ara
        symbol props adsfi
      cpp implementation data type element reports: type-reference=VideoReceiverReportVec
    BusinessPoint: category=STRUCTURE
      namespaces:
        symbol props ara
        symbol props adsfi
      8 x cpp implementation data type element, all with category=TYPE_REFERENCE:
        index: type-reference=int32_t
        x: type-reference=double
        y: type-reference=double
        xg: type-reference=double
        yg: type-reference=double
        angle: type-reference=double
        heading: type-reference=double
        direction: type-reference=int32_t
    BusinessPointVec: category=VECTOR, cpp-template-argument=BusinessPoint
      namespaces:
        symbol props ara
        symbol props adsfi
    BusinessPath: category=STRUCTURE
      namespaces:
        symbol props ara
        symbol props adsfi
      cpp implementation data type element points: type-reference=datatypes/BusinessPointVec
      cpp implementation data type element length: type-reference=double
    TrackPoint: category=STRUCTURE
      namespaces:
        symbol props ara
        symbol props adsfi
      6 x cpp implementation data type element, all with category=TYPE_REFERENCE:
        lon: type-reference=double
        lat: type-reference=double
        heading: type-reference=double
        index: type-reference=int32_t
        length: type-reference=double
        direction: type-reference=int8_t
    AppStatus: category=STRUCTURE
      namespaces:
        symbol props ara
        symbol props adsfi
      cpp implementation data type element record_status_track: type-reference=AppStatusMessage
      cpp implementation data type element record_status_fence: type-reference=AppStatusMessage
      cpp implementation data type element record_status_map: type-reference=AppStatusMessage
    SensorRadarPoint4D: category=STRUCTURE
      namespaces:
        symbol props ara
        symbol props adsfi
      23 x cpp implementation data type element, all with category=TYPE_REFERENCE:
        id: type-reference=int32_t
        motionStatus: type-reference=int32_t
        azimuth: type-reference=float
        elevation: type-reference=float
        range: type-reference=float
        range_rate: type-reference=float
        rangeStdDev: type-reference=float
        rangeRateStdDev: type-reference=float
        azimuthStdDev: type-reference=float
        elevationStdDev: type-reference=float
        existStatus: type-reference=int32_t
        falseAlarmProb: type-reference=int32_t
        heightConfidence: type-reference=int32_t
        snr: type-reference=uint8_t
        attribState: type-reference=int32_t
        ambg_state: type-reference=uint8_t
        modeFlag: type-reference=int32_t
        x: type-reference=float
        y: type-reference=float
        z: type-reference=float
        vx: type-reference=float
        vy: type-reference=float
        vz: type-reference=float
    MsgHafIMU: category=STRUCTURE
      namespaces:
        symbol props ara
        symbol props adsfi
      5 x cpp implementation data type element, all with category=TYPE_REFERENCE:
        imuHeader: type-reference=MsgHafHeader
        angularVelocity: type-reference=MsgPoint3D
        linearAcceleration: type-reference=MsgPoint3D
        imuStatus: type-reference=uint16_t
        temperature: type-reference=float
    AppRemoteControl: category=STRUCTURE
      namespaces:
        symbol props ara
        symbol props adsfi
      15 x cpp implementation data type element, all with category=TYPE_REFERENCE:
        header: type-reference=CommonHeader
        steering_wheel: type-reference=double
        gear: type-reference=int32_t
        brake: type-reference=double
        accelerator: type-reference=double
        remotectrl_flag: type-reference=int32_t
        estop_flag: type-reference=int32_t
        steer_torque: type-reference=double
        eng_status: type-reference=bool
        ctrl_level: type-reference=int32_t
        in_place: type-reference=bool
        tick: type-reference=int32_t
        speed_limit: type-reference=int32_t
        set_speed: type-reference=int32_t
        security_assist_enabled: type-reference=int32_t
    PlanningStatus: category=STRUCTURE
      namespaces:
        symbol props ara
        symbol props adsfi
      10 x cpp implementation data type element, all with category=TYPE_REFERENCE:
        header: type-reference=CommonHeader
        command_status: type-reference=uint8_t
        current_limit_speed: type-reference=double
        current_set_speed: type-reference=double
        current_set_angle: type-reference=double
        decision_info: type-reference=int32_t
        driving_center_trajectory: type-reference=MsgHafEgoTrajectory
        driving_left_boundary: type-reference=MsgHafEgoTrajectory
        driving_right_boundary: type-reference=MsgHafEgoTrajectory
        risk_level: type-reference=int32_t
    BusinessCommandParameter: category=STRUCTURE
      namespaces:
        symbol props ara
        symbol props adsfi
      20 x cpp implementation data type element, all with category=TYPE_REFERENCE:
        patrol_name: type-reference=String
        patrol_dest: type-reference=String
        patrol_type: type-reference=int32_t
        patrol_loop: type-reference=int32_t
        patrol_roads: type-reference=String
        max_speed: type-reference=double
        task_avoid_mode: type-reference=int32_t
        command: type-reference=int32_t
        follow_min_dis: type-reference=double
        follow_thw: type-reference=double
        follow_mode: type-reference=int32_t
        follow_x: type-reference=int32_t
        follow_y: type-reference=int32_t
        view_width: type-reference=int32_t
        view_height: type-reference=int32_t
        id: type-reference=int32_t
        return_lat: type-reference=double
        return_lon: type-reference=double
        fence: type-reference=String
        pose: type-reference=MsgHafPose
    BusinessCommand: category=STRUCTURE
      namespaces:
        symbol props ara
        symbol props adsfi
      10 x cpp implementation data type element, all with category=TYPE_REFERENCE:
        header: type-reference=CommonHeader
        business_mode: type-reference=int32_t
        business_path: type-reference=BusinessPath
        last_path: type-reference=MsgHafEgoTrajectory
        remote_ctl: type-reference=BusniessRemoteControl
        param: type-reference=BusinessCommandParameter
        estop_flag: type-reference=int32_t
        record_trigger_flag: type-reference=int32_t
        loc_strategy: type-reference=int32_t
        loc_control_mode: type-reference=int32_t
    BusinessTaskPoint: category=STRUCTURE
      namespaces:
        symbol props ara
        symbol props adsfi
      12 x cpp implementation data type element, all with category=TYPE_REFERENCE:
        header: type-reference=CommonHeader
        name: type-reference=String
        high: type-reference=double
        pitch: type-reference=double
        yaw: type-reference=double
        zoom: type-reference=int32_t
        lat: type-reference=double
        lon: type-reference=double
        dir: type-reference=double
        task_time: type-reference=int32_t
        type: type-reference=int32_t
        valid: type-reference=bool
    BusinessTaskPointVec: category=VECTOR, cpp-template-argument=BusinessTaskPoint
      namespaces:
        symbol props ara
        symbol props adsfi
    BusinessTaskPoints: category=STRUCTURE
      namespaces:
        symbol props ara
        symbol props adsfi
      cpp implementation data type element task_points: type-reference=BusinessTaskPointVec
    AppVision4CamsDataInType: category=STRUCTURE
      namespaces:
        symbol props ara
        symbol props adsfi
      14 x cpp implementation data type element, all with category=TYPE_REFERENCE:
        image_front_h30_valid: type-reference=bool
        image_front_h30: type-reference=AppImage
        image_front_h60_valid: type-reference=bool
        image_front_h60: type-reference=AppImage
        image_left_h90_valid: type-reference=bool
        image_left_h90: type-reference=AppImage
        image_right_h90_valid: type-reference=bool
        image_right_h90: type-reference=AppImage
        image_pano_left_valid: type-reference=bool
        image_pano_left: type-reference=AppImage
        image_pano_right_valid: type-reference=bool
        image_pano_right: type-reference=AppImage
        image_pano_back_valid: type-reference=bool
        image_pano_back: type-reference=AppImage
    CommonUdpPacketVec: category=VECTOR, cpp-template-argument=CommonUdpPacket
      namespaces:
        symbol props ara
        symbol props adsfi
    SensorRadarPacket: category=STRUCTURE
      namespaces:
        symbol props ara
        symbol props adsfi
      4 x cpp implementation data type element, all with category=TYPE_REFERENCE:
        header: type-reference=CommonHeader
        calibration: type-reference=CommonSensorCalibration
        msop_packet: type-reference=datatypes/CommonUdpPacketVec
        difop_packet: type-reference=CommonUdpPacket
    PerceptionSemanticObjVec: category=VECTOR, cpp-template-argument=PerceptionSemanticObj
      namespaces:
        symbol props ara
        symbol props adsfi
    PerceptionTerrainPatchVec: category=VECTOR, cpp-template-argument=PerceptionTerrainPatch
      namespaces:
        symbol props ara
        symbol props adsfi
    PerceptionStaticEnv: category=STRUCTURE
      namespaces:
        symbol props ara
        symbol props adsfi
      12 x cpp implementation data type element:
        header: type-reference=CommonHeader
        send_stamp: type-reference=double
        start_stamp: type-reference=double
        cell_size: type-reference=float
        semantic_objs: type-reference=datatypes/PerceptionSemanticObjVec
        terrain_patch_size: type-reference=float
        terrain_patches: type-reference=datatypes/PerceptionTerrainPatchVec
        map_width: type-reference=Int16
        map_height: type-reference=Int16
        vehicle_posx: type-reference=Int16
        vehicle_posy: type-reference=Int16
        reserved: type-reference=IdpUint8Vec
    MsgCameraDetectionResultVec: category=VECTOR, cpp-template-argument=MsgCameraDetectionResult
      namespaces:
        symbol props ara
        symbol props adsfi
    MsgCameraVPResult: category=STRUCTURE
      namespaces:
        symbol props ara
        symbol props adsfi
      cpp implementation data type element header: type-reference=MsgHafHeader
      cpp implementation data type element vp_result_vec: type-reference=MsgCameraDetectionResultVec
    VideoRTPParameter: category=STRUCTURE
      namespaces:
        symbol props ara
        symbol props adsfi
      5 x cpp implementation data type element, all with category=TYPE_REFERENCE:
        header: type-reference=CommonHeader
        ssrc: type-reference=int32_t
        peer_host: type-reference=String
        peer_port: type-reference=int32_t
        push_enabled: type-reference=int32_t
    BusinessPointVec: category=VECTOR, cpp-template-argument=BusinessPoint
      namespaces:
        symbol props ara
        symbol props adsfi
    AppGlobalPlannedPath: category=STRUCTURE
      namespaces:
        symbol props ara
        symbol props adsfi
      cpp implementation data type element head: type-reference=CommonHeader
      cpp implementation data type element path: type-reference=datatypes/BusinessPointVec
    VideoEncodedFrame: category=STRUCTURE
      namespaces:
        symbol props ara
        symbol props adsfi
      7 x cpp implementation data type element, all with category=TYPE_REFERENCE:
        header: type-reference=CommonHeader
        encoding: type-reference=int32_t
        key_frame: type-reference=int32_t
        frame_size: type-reference=int32_t
        frame_data: type-reference=IdpUint8Vec
        fps: type-reference=double
        pts: type-reference=double
    MsgHafRadarTrackDataVec: category=VECTOR, cpp-template-argument=MsgHafRadarTrackData
      namespaces:
        symbol props ara
        symbol props adsfi
    MsgHafRadarTrackArrayFrame: category=STRUCTURE
      namespaces:
        symbol props ara
        symbol props adsfi
      7 x cpp implementation data type element, all with category=TYPE_REFERENCE:
        timestamp: type-reference=MsgHafTime
        frameID: type-reference=String
        sensorID: type-reference=uint8_t
        seq: type-reference=uint32_t
        trackList: type-reference=MsgHafRadarTrackDataVec
        yawRate: type-reference=double
        vehicleSpeed: type-reference=double
    MsgImageDataVec: category=VECTOR, cpp-template-argument=MsgImageData
      namespaces:
        symbol props ara
        symbol props adsfi
    MsgImageDataList: category=STRUCTURE
      namespaces:
        symbol props ara
        symbol props adsfi
      cpp implementation data type element header: type-reference=MsgHafHeader
      cpp implementation data type element images: type-reference=datatypes/MsgImageDataVec
    PerceptionUtraDataVec: category=VECTOR, cpp-template-argument=PerceptionUtraData
      namespaces:
        symbol props ara
        symbol props adsfi
    PerceptionSemanticObjVec: category=VECTOR, cpp-template-argument=PerceptionSemanticObj
      namespaces:
        symbol props ara
        symbol props adsfi
    PerceptionTerrainPatchVec: category=VECTOR, cpp-template-argument=PerceptionTerrainPatch
      namespaces:
        symbol props ara
        symbol props adsfi
    PerceptionSemanticMap: category=STRUCTURE
      namespaces:
        symbol props ara
        symbol props adsfi
      11 x cpp implementation data type element:
        header: type-reference=CommonHeader
        trigger_stamp: type-reference=double
        cell_size: type-reference=float
        ultra_results: type-reference=PerceptionUtraDataVec
        semantic_objs: type-reference=datatypes/PerceptionSemanticObjVec
        terrain_patches: type-reference=datatypes/PerceptionTerrainPatchVec
        reserved: type-reference=IdpUint8Vec
        map_width: type-reference=Int16
        map_height: type-reference=Int16
        vehicle_posx: type-reference=Int16
        vehicle_posy: type-reference=Int16
    MsgHafRadarDetectDataVec: category=VECTOR, cpp-template-argument=MsgHafRadarDetectData
      namespaces:
        symbol props ara
        symbol props adsfi
    MsgHafRadarDetectArrayFrame: category=STRUCTURE
      namespaces:
        symbol props ara
        symbol props adsfi
      11 x cpp implementation data type element, all with category=TYPE_REFERENCE:
        timestamp: type-reference=MsgHafTime
        frameID: type-reference=String
        sensorID: type-reference=uint8_t
        seq: type-reference=uint32_t
        detectList: type-reference=MsgHafRadarDetectDataVec
        maxDistanceOverAzimuthList: type-reference=double
        azimuthForMaxDistanceList: type-reference=double
        factorDistanceOverElevationList: type-reference=double
        elevationForFactorMaxDistanceList: type-reference=double
        maxDistanceDueToProgram: type-reference=double
        minDistanceDueToProgram: type-reference=double
    MsgHafGnssInfo: category=STRUCTURE
      namespaces:
        symbol props ara
        symbol props adsfi
      30 x cpp implementation data type element, all with category=TYPE_REFERENCE:
        header: type-reference=MsgHafHeader
        latitude: type-reference=double
        longitude: type-reference=double
        elevation: type-reference=double
        utmPosition: type-reference=MsgPoint3D
        utmZoneNum: type-reference=int32_t
        utmZoneChar: type-reference=uint8_t
        heading_valid: type-reference=uint8_t
        pos_valid: type-reference=uint8_t
        attitude: type-reference=MsgPoint3D
        sdPosition: type-reference=MsgPoint3D
        sdVelocity: type-reference=MsgPoint3D
        sdAttitude: type-reference=MsgPoint3D
        second: type-reference=double
        satUseNum: type-reference=int32_t
        satInViewNum: type-reference=int32_t
        solutionStatus: type-reference=uint16_t
        positionType: type-reference=uint16_t
        linearVelocity: type-reference=MsgPoint3D
        attitudeDual: type-reference=MsgPoint3D
        sdAngleDual: type-reference=MsgPoint3D
        baseLineLengthDual: type-reference=double
        solutionStatusDual: type-reference=int32_t
        positionTypeDual: type-reference=int32_t
        solutionSourceDual: type-reference=int32_t
        cep68: type-reference=double
        cep95: type-reference=double
        pDop: type-reference=float
        hDop: type-reference=float
        vDop: type-reference=float
    SensorRadarPoint4DVec: category=VECTOR, cpp-template-argument=SensorRadarPoint4D
      namespaces:
        symbol props ara
        symbol props adsfi
    SensorRadarPointCloud: category=STRUCTURE
      namespaces:
        symbol props ara
        symbol props adsfi
      cpp implementation data type element header: type-reference=CommonHeader
      cpp implementation data type element objs: type-reference=SensorRadarPoint4DVec
    AppPilotedEnabling: category=STRUCTURE
      namespaces:
        symbol props ara
        symbol props adsfi
      cpp implementation data type element enabling: type-reference=int32_t
    VehicleActControl: category=STRUCTURE
      namespaces:
        symbol props ara
        symbol props adsfi
      4 x cpp implementation data type element, all with category=TYPE_REFERENCE:
        header: type-reference=CommonHeader
        lat_control: type-reference=VehicleLatControl
        lon_control: type-reference=VehicleLonControl
        sensor_control: type-reference=VehicleSensorControl
    VehicleSensorState: category=STRUCTURE
      namespaces:
        symbol props ara
        symbol props adsfi
      21 x cpp implementation data type element, all with category=TYPE_REFERENCE:
        VCU_fault: type-reference=uint8_t
        vehicle_total_mile: type-reference=float
        vehicle_ready_status: type-reference=uint8_t
        offroad_working_mode: type-reference=uint8_t
        parking_mode: type-reference=uint8_t
        motor_mode: type-reference=uint8_t
        power_mode: type-reference=uint8_t
        speed_limit: type-reference=uint8_t
        power_status: type-reference=uint8_t
        low_beam_status: type-reference=uint8_t
        far_beam_status: type-reference=uint8_t
        turn_left_light_status: type-reference=uint8_t
        turn_right_light_status: type-reference=uint8_t
        lidar_power_status: type-reference=uint8_t
        radar_power_status: type-reference=uint8_t
        night_camera_power_status: type-reference=uint8_t
        horn_status: type-reference=uint8_t
        fuel_level: type-reference=float
        remaining_mileage: type-reference=float
        bms_battery_soc: type-reference=uint8_t
        voltage: type-reference=float
    VehicleInformation: category=STRUCTURE
      namespaces:
        symbol props ara
        symbol props adsfi
      4 x cpp implementation data type element, all with category=TYPE_REFERENCE:
        header: type-reference=CommonHeader
        vehicle_sensor_state: type-reference=VehicleSensorState
        vehicle_act_state: type-reference=VehicleActState
        wheel_speed: type-reference=MsgHafWheelSpeedList
    MsgHafUint8WithValid: category=STRUCTURE
      namespaces:
        symbol props ara
        symbol props adsfi
      cpp implementation data type element value: type-reference=uint8_t
      cpp implementation data type element confidence: type-reference=uint8_t
    TaskExecuteStatus: category=STRUCTURE
      namespaces:
        symbol props ara
        symbol props adsfi
      8 x cpp implementation data type element, all with category=TYPE_REFERENCE:
        type: type-reference=uint8_t
        status: type-reference=uint8_t
        current_limit_speed: type-reference=double
        task_points: type-reference=BusinessTaskPoints
        distance_to_nearest: type-reference=double
        total_mileage: type-reference=double
        current_mileage: type-reference=double
        progress: type-reference=uint8_t
    TrackPointVec: category=VECTOR, cpp-template-argument=TrackPoint
      namespaces:
        symbol props ara
        symbol props adsfi
    TrackPath: category=STRUCTURE
      namespaces:
        symbol props ara
        symbol props adsfi
      5 x cpp implementation data type element, all with category=TYPE_REFERENCE:
        header: type-reference=CommonHeader
        status: type-reference=int32_t
        avoid: type-reference=int32_t
        speed: type-reference=double
        points: type-reference=TrackPointVec
package /serviceInterface
  28 x dds service interface deployment:
    SensorImageListServiceInterface_DdsDeployment: service-interface=MsgImageDataListServiceInterface, service-interface-id=1
      dds event deployment EventImageListDdsDeployment: event=EventImageList, frag-size=409600, list-size=20, topic-name=TopicOfEventImageList
    SensorLidarPointCloudServiceInterface_DdsDeployment: service-interface=SensorLidarPointCloudServiceInterface, service-interface-id=2
      dds event deployment EventPointCloud2DdsDeployment: event=EventPointCloud2, frag-size=10240000, list-size=20, topic-name=TopicOfEventPointCloud2
    VehicleInfomationServiceInterface_DdsDeployment: service-interface=VehicleInfomationServiceInterface, service-interface-id=3
      dds event deployment EventVehicleInfoDdsDeployment: event=EventVehicleInfo, frag-size=409600, list-size=20, topic-name=TopicOfEventVehicleInfo
    VisionSegmentServiceInterface_DdsDeployment: service-interface=VisionSegmentServiceInterface, service-interface-id=4
      dds event deployment EventVisionSegmentDdsDeployment: event=EventVisionSegment, frag-size=10240000, list-size=20, topic-name=TopicOfEventVisionSegment
    PlanningStatusServiceInterface_DdsDeployment: service-interface=PlanningStatusServiceInterface, service-interface-id=5
      dds event deployment EventPlanningStatusDdsDeployment: event=EventPlanningStatus, frag-size=409600, list-size=20, topic-name=TopicOfEventPlanningStatus
    BodyCommandServiceInterface_DdsDeployment: service-interface=BodyCommandServiceInterface, service-interface-id=6
      dds event deployment EventVehicleActControlDdsDeployment: event=EventVehicleActControl, frag-size=409600, list-size=20, topic-name=TopicOfEventVehicleActControl
    RemoteControlServiceInterface_DdsDeployment: service-interface=RemoteControlServiceInterface, service-interface-id=7
      dds event deployment EventRCAppRemoteCtlDdsDeployment: event=EventRCAppRemoteCtl, frag-size=409600, list-size=20, topic-name=TopicOfEventRCAppRemoteCtl
    VideoRtpServiceInterface_DdsDeployment: service-interface=VideoRtpServiceInterface, service-interface-id=8
      dds event deployment EventVideoRtpParamterDdsDeployment: event=EventVideoRtpParamter, frag-size=409600, list-size=20, topic-name=TopicOfEventVideoRtpParamter
    TrackingServiceInterface_DdsDeployment: service-interface=TrackingServiceInterface, service-interface-id=10
      dds event deployment EventTrackPathDdsDeployment: event=TrackingServiceInterface/EventBusinessCommand, frag-size=409600, list-size=20, topic-name=TopicOfEventTrackPath
    BusinessCommandServiceInterface_DdsDeployment: service-interface=BusinessCommandServiceInterface, service-interface-id=12
      dds event deployment EventBusinessCommandDdsDeployment: event=BusinessCommandServiceInterface/EventBusinessCommand, frag-size=409600, list-size=20, topic-name=TopicOfEventBusinessCommand
    SensorImageServiceInterface_DdsDeployment: service-interface=SensorImageServiceInterface, service-interface-id=13
      dds event deployment EventSensorImageDdsDeployment: event=EventSensorImage, frag-size=409600, list-size=20, topic-name=TopicOfEventSensorImage
    RadarPointCloudServiceInterface_DdsDeployment: service-interface=RadarPointCloudServiceInterface, service-interface-id=15
      dds event deployment EventRadarPointCloudDdsDeployment: event=EventRadarPointCloud, frag-size=409600, list-size=20, topic-name=TopicOfEventRadarPointCloud
    SensorWheelSpeedServiceInterface_DdsDeployment: service-interface=SensorWheelSpeedServiceInterface, service-interface-id=16
      dds event deployment EventWheelSpeedDdsDeployment: event=EventWheelSpeed, frag-size=409600, list-size=20, topic-name=TopicOfEventWheelSpeed
    SensorGpsServiceInterface_DdsDeployment: service-interface=SensorGpsServiceInterface, service-interface-id=17
      dds event deployment EventGpsDdsDeployment: event=EventGps, frag-size=409600, list-size=20, topic-name=TopicOfEventGps
    TaskExecuteStatusServiceInterface_DdsDeployment: service-interface=TaskExecuteStatusServiceInterface, service-interface-id=18
      dds event deployment EventTaskExecuteStatusDdsDeployment: event=EventTaskExecuteStatus, frag-size=409600, list-size=20, topic-name=TopicOfEventTaskExecuteStatus
    SensorImuServiceInterface_DdsDeployment: service-interface=SensorImuServiceInterface, service-interface-id=19
      dds event deployment EventSensorImuDdsDeployment: event=EventSensorImu, frag-size=409600, list-size=20, topic-name=TopicOfEventSensorImu
    BagStatusServiceInterface_DdsDeployment: service-interface=BagStatusServiceInterface, service-interface-id=20
      dds event deployment EventBagStatusDdsDeployment: event=EventBagStatus, frag-size=409600, list-size=20, topic-name=TopicOfEventBagStatus
    FaultDataServiceInterface_DdsDeployment: service-interface=FaultDataServiceInterface, service-interface-id=21
      dds event deployment EventFaultDataDdsDeployment: event=EventFaultData, frag-size=409600, list-size=20, topic-name=TopicOfEventFaultData
    PerceptionFinalObjectsServiceInterface_DdsDeployment: service-interface=PerceptionFinalObjectsServiceInterface, service-interface-id=22
      dds event deployment EventPerceptionFinalObjectsDdsDeployment: event=EventPerceptionFinalObjects, frag-size=409600, list-size=20, topic-name=TopicOfEventPerceptionFinalObjects
    PerceptionStaticEnvServiceInterface_DdsDeployment: service-interface=PerceptionStaticEnvServiceInterface, service-interface-id=23
      dds event deployment EventPerceptionStaticEnvDdsDeployment: event=EventPerceptionStaticEnv, frag-size=409600, list-size=20, topic-name=TopicOfEventPerceptionStaticEnv
    PlanningTrajectoryServiceInterface_DdsDeployment: service-interface=PlanningTrajectoryServiceInterface, service-interface-id=25
      dds event deployment EventPlanningTrajectoryDdsDeployment: event=EventPlanningTrajectory, frag-size=409600, list-size=20, topic-name=TopicOfEventPlanningTrajectory
    VehicleSensorControlServiceInterface_DdsDeployment: service-interface=VehicleSensorControlServiceInterface, service-interface-id=26
      dds event deployment EventVideoEditorParameterDdsDeployment: event=EventVehicleSensorControl, frag-size=409600, list-size=20, topic-name=TopicOfEventVideoEditorParameter
    TaskManageStatusServiceInterface_DdsDeployment: service-interface=TaskManageStatusServiceInterface, service-interface-id=27
      dds event deployment EventTaskManageStatusDdsDeployment: event=EventTaskManageStatus, frag-size=409600, list-size=20, topic-name=TopicOfEventTaskManageStatus
    AppVideoProfileServiceInterface_DdsDeployment: service-interface=AppVideoProfileServiceInterface, service-interface-id=29
      dds event deployment EventAppVideoProfileDdsDeployment: event=EventAppVideoProfile, frag-size=409600, list-size=20, topic-name=TopicOfEventAppVideoProfile
    SensorCompressedImageListServiceInterface_DdsDeployment: service-interface=SensorCompressedImageListServiceInterface, service-interface-id=30
      dds event deployment EventCompressedImageListDdsDeployment: event=EventCompressedImageList, frag-size=409600, list-size=20, topic-name=TopicOfEventCompressedImageList
    SensorLidarPacketServiceInterface_DdsDeployment: service-interface=SensorLidarPacketServiceInterface, service-interface-id=31
      dds event deployment EventLidarPacketDdsDeployment: event=EventLidarPacket, frag-size=409600, list-size=20, topic-name=TopicOfEventLidarPacket
    SensorRadarPacketServiceInterface_DdsDeployment: service-interface=SensorRadarPacketServiceInterface, service-interface-id=32
      dds event deployment EventSensorRadarPacketDdsDeployment: event=EventSensorRadarPacket, frag-size=409600, list-size=20, topic-name=TopicOfEventSensorRadarPacket
    VideoEncodingPerfServiceInterface_DdsDeployment: service-interface=VideoEncodingPerfServiceInterface, service-interface-id=9
      dds event deployment EventVideoEncodingPerfDdsDeployment: event=EventVideoEncodingPerf, frag-size=409600, list-size=20, topic-name=TopicOfEventVideoEncodingPerf
